# LPC54102_cm0plus register map
Vendor: nxp.com; File version: 1.0
CPU: CM0PLUS r0p0, little endian, no MPU, no FPU, VTOR, 2 interrupt priority bits
Registers are 32-bit, read-write, reset 0x0 unless marked. A register's access mark holds for its fields unless they carry their own. Offsets are from the block's base; [hi:lo] are bit positions; {n}, {i} and the like mark numbered series.

## ITM — Instrumentation Trace Macrocell Registers
Base 0xE0000000; register names take the prefix ITM_
{0x0+4i} STIM{i}_READ (reset mask 0xFFFFFFFE) (STIM{i}_READ_STIM{i}_WRITE view) (i=0..31) — Stimulus Port Register {i} (for reading)
  [0] FIFOREADY
{0x0+4i} STIM{i}_WRITE reset not defined (STIM{i}_READ_STIM{i}_WRITE view) (i=0..31) — Stimulus Port Register {i} (for writing)
  [31:0] STIMULUS — Data write to the stimulus port FIFO, for forwarding as a software event packet.
0xE00 TER — Trace Enable Register
  [31:0] STIMENA — For bit STIMENA[n], in register ITM_TERx: 0 = Stimulus port (32x + n) disabled 1 = Stimulus port (32x + n) enabled
0xE40 TPR — Trace Privilege Register
  [3:0] PRIVMASK — Bit mask to enable tracing on ITM stimulus ports: Bit [0] = stimulus port [7:0] Bit [1] = stimulus port [15:8] Bit [2] = stimulus port [23:16] Bit [3] = stimulus port [31:24]
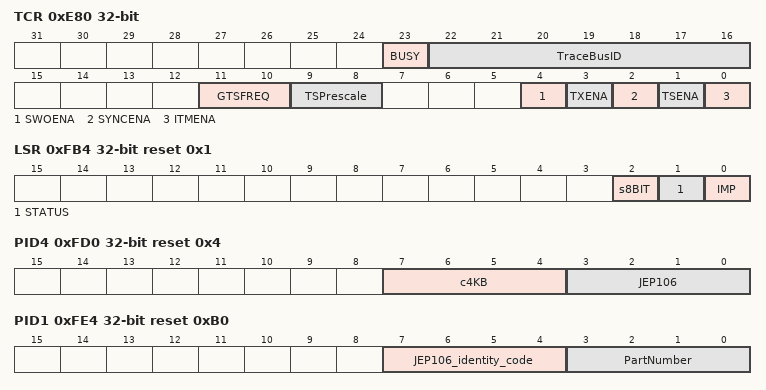
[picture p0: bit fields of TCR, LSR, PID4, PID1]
0xE80 TCR — Trace Control Register
  [23] BUSY ro — Indicates whether the ITM is currently processing events: 0: ITM is not processing any events. 1: ITM events present and being drained.
    0=ITM is not processing any events; 1=ITM events present and beeing drained
  [22:16] TraceBusID — Identifier for multi-source trace stream formatting. If multi-source trace is in use, the debugger must write a non-zero value to this field.
  [11:10] GTSFREQ — Global timestamp frequency. Defines how often the ITM generates a global timestamp, based on the global timestamp clock frequency, or disables generation of global timestamps.
    0=Disable generation of global timestamps; 1=Generate timestamp request whenever the ITM detects a change in global timestamp counter bits [47:7]. This is approximately every 128 cycles.; 2=Generate timestamp request whenever the ITM detects a change in global timestamp counter bits [47:13]. This is approximately every 8192 cycles.; 3=Generate a timestamp after every packet, if the output FIFO is empty
  [9:8] TSPrescale — Local timestamp prescaler, used with the trace packet reference clock.
    0=No prescaling; 1=Divide by 4; 2=Divide by 16; 3=Divide by 64
  [4] SWOENA
    0=Timestamp counter uses the processor system clock; 1=Timestamp counter uses asynchronous clock from the TPIU interface
  [3] TXENA
    0=Disabled; 1=Enabled
  [2] SYNCENA
    0=Disabled; 1=Enabled
  [1] TSENA
    0=Disabled; 1=Enabled
  [0] ITMENA
    0=Disabled; 1=Enabled
0xFB0 LAR reset not defined — Lock Access Register
  [31:0] WriteAccessCode — Write Access Code. A write of 0xC5ACCE55 enables further write access to this device. An invalid write will have the affect of removing write access.
0xFB4 LSR ro reset 0x1 (reset mask 0xFFFFFFFD) — Lock Status Register
  [2] s8BIT — Access Lock Register size. This bit reads 0 to indicate a 32-bit register is present.
  [1] STATUS — Lock Status. This bit is HIGH when the device is locked, and LOW when unlocked.
  [0] IMP — Lock mechanism is implemented. This bit always reads 1.
0xFD0 PID4 ro reset 0x4 — Peripheral Identification Register 4.
  [7:4] c4KB — 4KB Count
  [3:0] JEP106 — JEP106 continuation code.
{0xFC0+4i} PID{i} ro (i=5..7) — Peripheral Identification Register {i}.
0xFE0 PID0 ro reset 0x2 — Peripheral Identification Register 0.
  [7:0] PartNumber — Part Number [7:0]
0xFE4 PID1 ro reset 0xB0 — Peripheral Identification Register 1.
  [7:4] JEP106_identity_code — JEP106 identity code [3:0]
  [3:0] PartNumber — Part Number [11:8]
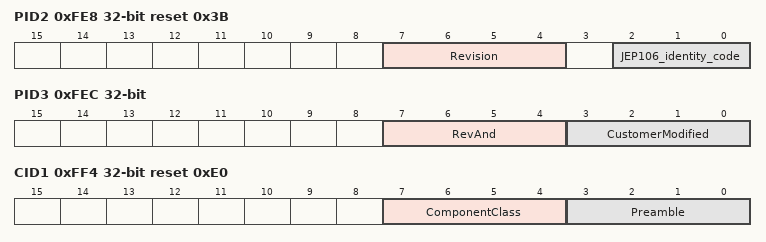
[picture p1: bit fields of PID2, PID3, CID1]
0xFE8 PID2 ro reset 0x3B — Peripheral Identification Register 2.
  [7:4] Revision
  [2:0] JEP106_identity_code — JEP106 identity code [6:4]
0xFEC PID3 ro — Peripheral Identification Register 3.
  [7:4] RevAnd, [3:0] CustomerModified
0xFF0 CID0 ro reset 0xD — Component Identification Register 0.
  [7:0] Preamble
0xFF4 CID1 ro reset 0xE0 — Component Identification Register 1.
  [7:4] ComponentClass
    1=ROM table; 9=CoreSight component; 15=PrimeCell of system component with no standardized register layout, for backward compatibility
  [3:0] Preamble
0xFF8 CID2 ro reset 0x5 — Component Identification Register 2.
  [7:0] Preamble
0xFFC CID3 ro reset 0xB1 — Component Identification Register 3.
  [7:0] Preamble
